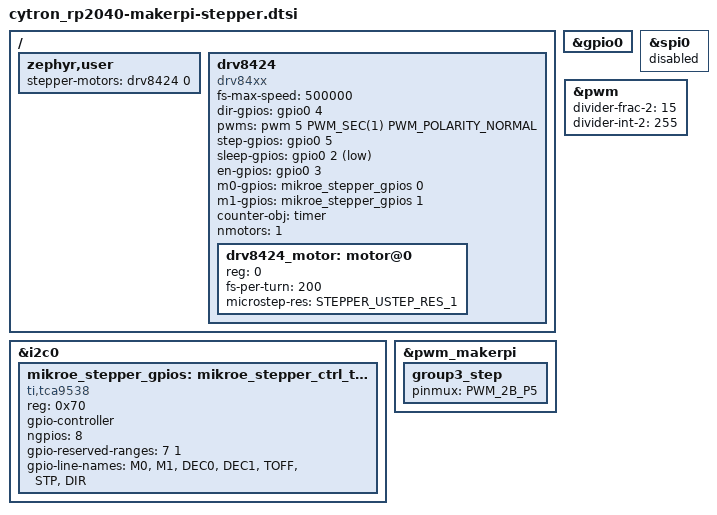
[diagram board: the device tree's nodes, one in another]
/*
 * Copyright (c) 2023-2024 TiaC Systems
 * SPDX-License-Identifier: Apache-2.0
 */

#include <zephyr/dt-bindings/stepper/stepper.h>
#include <zephyr/dt-bindings/gpio/gpio.h>

/ {
	zephyr,user {
		stepper-motors = <&drv8424 0>;
	};
};

/* Grove connector 4 */
&i2c0 {
        status = "okay";

        mikroe_stepper_gpios: mikroe_stepper_ctrl_tca9538a@70 {
                status = "okay";
                compatible = "ti,tca9538";

                reg = < 0x70 >;

                gpio-controller;
                ngpios = < 8 >;
                #gpio-cells = < 2 >;

                gpio-reserved-ranges = < 7 1 >;

                gpio-line-names =
			"M0",
			"M1",
			"DEC0",
			"DEC1",
			"TOFF",
			"STP",
			"DIR";
        };
};

/ {

        drv8424: drv8424 {
                status = "okay";
                compatible = "drv84xx";

                fs-max-speed = < 500000 >; /* Steps/s */

                dir-gpios = < &gpio0 4 0 >;
		pwms = <&pwm 5 PWM_SEC(1) PWM_POLARITY_NORMAL>;
		step-gpios = <&gpio0 5 0>;
                sleep-gpios = < &gpio0 2 GPIO_ACTIVE_LOW >;
                en-gpios  = < &gpio0 3 0 >;
                m0-gpios = < &mikroe_stepper_gpios 0 0 >;
                m1-gpios = < &mikroe_stepper_gpios 1 0 >;
		counter-obj = <&timer>;

		nmotors = < 1 >;
		#address-cells = < 1 >;
		#size-cells = < 0 >;
		#stepper-motor-cells = < 1 >;

		drv8424_motor: motor@0 {
			reg = < 0 >;
			fs-per-turn = < 200 >;
			microstep-res = < STEPPER_USTEP_RES_1 >;
		};
	};
};

&i2c0 {
	status = "okay";
};

&gpio0 {
	status = "okay";
};

&spi0 {
	status = "disabled";
};

&pwm_makerpi {
       group3_step {
       	 pinmux = <PWM_2B_P5>;		/* GP5: PWM2CHB (5) */
        };
};

&pwm {
       divider-frac-2 = <15>;
       divider-int-2 = <255>;
};
